# I94100_v1_3 register map
File version: 1.0
Registers are 32-bit, read-write, reset 0x0 unless marked. A register's access mark holds for its fields unless they carry their own. Offsets are from the block's base; [hi:lo] are bit positions; {n}, {i} and the like mark numbered series; 'fields as' and 'values as' point back to an identical list; <NAME> marks a mode.

## TMR23 — TIMER Register Map
Base 0x40051000
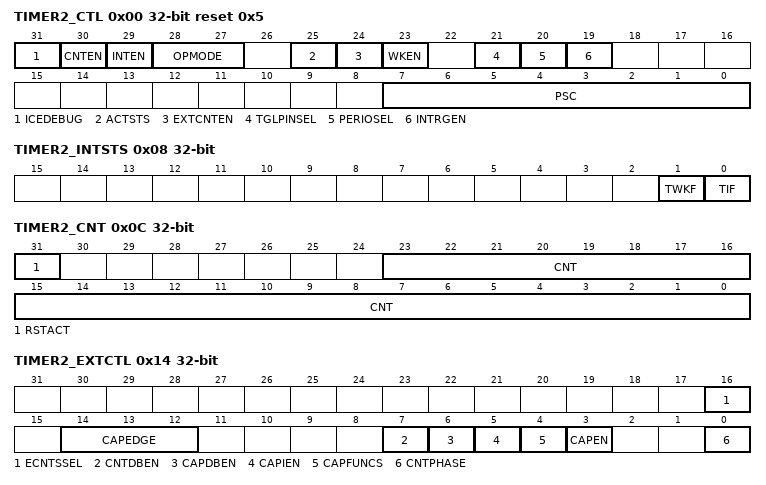
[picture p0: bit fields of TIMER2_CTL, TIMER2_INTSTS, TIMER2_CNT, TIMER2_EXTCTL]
0x00 TIMER2_CTL reset 0x5 — Timer2 Control Register
  [31] ICEDEBUG — ICE Debug Mode Acknowledge Disable Control (Write Protected). TIMER counter will keep going no matter CPU is held by ICE or not. Note: This bit is write protected. Refer to the SYS_REGLCTL register.
    0=ICE debug mode acknowledgement effects TIMER counting; 1=ICE debug mode acknowledgement Disabled
  [30] CNTEN — Timer Counting Enable Bit. Note3: Set enable/disable this bit needs 2 * TMR_CLK period to become active, user can read ACTSTS (TIMERx_CTL[25]) to check enable/disable command is completed or not.
    0=Stops/Suspends counting; 1=Starts counting
  [29] INTEN — Timer Interrupt Enable Bit. Note: If this bit is enabled, when the timer time-out interrupt flag TIF is set to 1, the timer interrupt signal is generated and inform to CPU.
    0=Timer time-out interrupt Disabled; 1=Timer time-out interrupt Enabled
  [28:27] OPMODE — Timer Counting Mode Select
    0=The Timer controller is operated in One-shot mode; 1=The Timer controller is operated in Periodic mode; 2=The Timer controller is operated in Toggle-output mode; 3=The Timer controller is operated in Continuous Counting mode
  [25] ACTSTS ro — Timer Active Status Bit (Read Only). This bit indicates the 24-bit up counter status. Note: This bit may active when CNT 0 transition to CNT 1.
    0=24-bit up counter is not active; 1=24-bit up counter is active
  [24] EXTCNTEN — Event Counter Mode Enable Bit. This bit is for external counting pin function enabled. Note: When timer is used as an event counter, this bit should be set to 1 and select PCLK as timer clock source.
    0=Event counter mode Disabled; 1=Event counter mode Enabled
  [23] WKEN — Wake-up Function Enable Bit. If this bit is set to 1, while timer interrupt flag TIF (TIMERx_INTSTS[0]) is 1 and INTEN (TIMERx_CTL[29]) is enabled, the timer interrupt signal will generate a wake-up trigger event to CPU.
    0=Wake-up function Disabled if timer interrupt signal generated; 1=Wake-up function Enabled if timer interrupt signal generated
  [21] TGLPINSEL — Toggle-output Pin Select
    0=Toggle mode output to TMx (Timer Event Counter Pin); 1=Toggle mode output to TMx_EXT (Timer External Capture Pin)
  [20] PERIOSEL — Periodic Mode Behavior Selection Enable Bit. If updated CMPDAT value < CNT, CNT will be reset to default value.
    0=The behavior selection in periodic mode is Disabled; 1=The behavior selection in periodic mode is Enabled
  [19] INTRGEN — Inter-timer Trigger Mode Enable Control. Setting this bit will enable the inter-timer trigger capture function. The Timer0/2 will be in event counter mode and counting with external clock source or event.Also, Timer1/3 will be in trigger-counting mode of capture function. Note: For Timer1/3, this bit is ignored and the read back value is always 0.
    0=Inter-Timer Trigger Capture mode Disabled; 1=Inter-Timer Trigger Capture mode Enabled
  [7:0] PSC — Prescale Counter. Note: Overwriting prescale counter value will reset internal 8-bit prescale counter and 24-bit up counter value.
0x04 TIMER2_CMP — Timer2 Comparator Register
  [23:0] CMPDAT — Timer Comparator Value. CMPDAT is a 24-bit compared value register. When the internal 24-bit up counter value is equal to CMPDAT value, the TIF (TIMERx_INTSTS[0] Timer Interrupt Flag) will set to 1. Note1: Never write 0x0 or 0x1 in CMPDAT field, or the core will run into unknown state. Note2: When timer is operating at continuous counting mode, the 24-bit up counter will keep counting continuously even if user writes a new value into CMPDAT field. But if timer is operating at other modes, the 24-bit up counter will restart counting from 0 and using newest CMPDAT value to be the timer compared value while user writes a new value into CMPDAT field.
0x08 TIMER2_INTSTS — Timer2 Interrupt Status Register
  [1] TWKF — Timer Wake-up Flag. This bit indicates the interrupt wake-up flag status of timer. Note: This bit is cleared by writing 1 to it.
    0=Timer does not cause CPU wake-up; 1=CPU wake-up from Power-down mode if timer time-out interrupt signal generated
  [0] TIF — Timer Interrupt Flag. This bit indicates the interrupt flag status of Timer while 24-bit timer up counter CNT (TIMERx_CNT[23:0]) value reaches to CMPDAT (TIMERx_CMP[23:0]) value. Note: This bit is cleared by writing 1 to it.
    0=No effect; 1=CNT value matches the CMPDAT value
0x0C TIMER2_CNT — Timer2 Data Register
  [31] RSTACT ro — Timer Data Register Reset Active (Read Only). This bit indicates if the counter reset operation active. When user writes this CNT register, timer starts to reset its internal 24-bit timer up-counter to 0 and reload 8-bit pre-scale counter. At the same time, timer set this flag to 1 to indicate the counter reset operation is in progress. Once the counter reset operation done, timer clear this bit to 0 automatically. Note: This bit is read only.
    0=Reset operation is done; 1=Reset operation triggered by writing TIMERx_CNT is in progress
  [23:0] CNT — Timer Data Register. Read operation. Read this register to get CNT value. For example: If EXTCNTEN (TIMERx_CTL[24] ) is 0, user can read CNT value for getting current 24-bit counter value. If EXTCNTEN (TIMERx_CTL[24] ) is 1, user can read CNT value for getting current 24-bit event input counter value. Write operation. Writing any value to this register will reset current CNT value to 0 and reload internal 8-bit prescale counter.
0x10 TIMER2_CAP ro — Timer2 Capture Data Register
  [23:0] CAPDAT — Timer Capture Data Register (Read Only). When CAPEN (TIMERx_EXTCTL[3]) bit is set, CAPFUNCS (TIMERx_EXTCTL[4]) bit is 0, and a transition on TMx_EXT pin matched the CAPEDGE (TIMERx_EXTCTL[14:12]) setting, CAPIF (TIMERx_EINTSTS[0]) will set to 1 and the current timer counter value CNT (TIMERx_CNT[23:0]) will be auto-loaded into this CAPDAT field.
0x14 TIMER2_EXTCTL — Timer2 External Control Register
  [16] ECNTSSEL — Event Counter Source Selection to Trigger Event Counter Function
    0=Event Counter input source is from TMx (x= 0~3) pin; 1=Reserved Event Counter input source is from USB internal SOF output signal
  [14:12] CAPEDGE — Timer External Capture Pin Edge Detect. When first capture event is generated, the CNT (TIMERx_CNT[23:0]) will be reset to 0 and first CAPDAT (TIMERx_CAP[23:0]) should be to 0.
    0=Capture event occurred when detect falling edge transfer on TMx_EXT (x= 0~3) pin; 1=Capture event occurred when detect rising edge transfer on TMx_EXT (x= 0~3) pin; 2=Capture event occurred when detect both falling and rising edge transfer on TMx_EXT (x= 0~3) pin, and first capture event occurred at falling edge transfer; 3=Capture event occurred when detect both rising and falling edge transfer on TMx_EXT (x= 0~3) pin, and first capture event occurred at rising edge transfer; 6=First capture event occurred at falling edge, follows capture events are at rising edge transfer on TMx_EXT (x= 0~3) pin; 7=First capture event occurred at rising edge, follows capture events are at falling edge transfer on TMx_EXT (x= 0~3) pin
  [7] CNTDBEN — Timer Counter Pin De-bounce Enable Bit. Note: If this bit is enabled, the edge detection of TMx pin is detected with de-bounce circuit.
    0=TMx (x= 0~3) pin de-bounce Disabled; 1=TMx (x= 0~3) pin de-bounce Enabled
  [6] CAPDBEN — Timer External Capture Pin De-bounce Enable Bit. Note: If this bit is enabled, the edge detection of TMx_EXT pin output is detected with de-bounce circuit.
    0=TMx_EXT (x= 0~3) pin de-bounce Disabled; 1=TMx_EXT (x= 0~3) pin de-bounce Enabled
  [5] CAPIEN — Timer External Capture Interrupt Enable Bit
    0=TMx_EXT (x= 0~3) pin detection Interrupt Disabled; 1=TMx_EXT (x= 0~3) pin detection Interrupt Enabled
  [4] CAPFUNCS — Capture Function Selection
    0=External Capture Mode Enabled; 1=External Reset Mode Enabled
  [3] CAPEN — Timer External Capture Pin Enable Bit. This bit enables the TMx_EXT capture pin input function.
    0=TMx_EXT (x= 0~3) pin Disabled; 1=TMx_EXT (x= 0~3) pin Enabled
  [0] CNTPHASE — Timer External Count Phase
    0=A falling edge of external counting pin will be counted; 1=A rising edge of external counting pin will be counted
0x18 TIMER2_EINTSTS — Timer2 External Interrupt Status Register
  [0] CAPIF — Timer External Capture Interrupt Flag. This bit indicates the timer external capture interrupt flag status. Note3: There is a new incoming capture event detected before CPU clearing the CAPIF status. If the above condition occurred, the Timer will keep register TIMERx_CAP unchanged and drop the new capture value.
    0=TMx_EXT (x= 0~3) pin interrupt did not occur; 1=TMx_EXT (x= 0~3) pin interrupt occurred
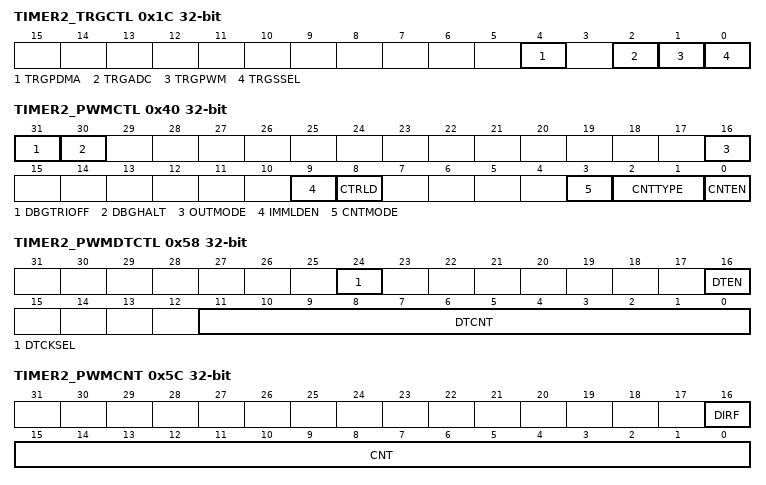
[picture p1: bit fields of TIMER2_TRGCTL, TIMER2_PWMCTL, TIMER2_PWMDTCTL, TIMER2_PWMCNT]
0x1C TIMER2_TRGCTL — Timer2 Trigger Control Register
  [4] TRGPDMA — Trigger PDMA Enable Bit. If this bit is set to 1, each timer time-out event or capture event can be triggered PDMA transfer.
    0=Timer interrupt trigger PDMA Disabled; 1=Timer interrupt trigger PDMA Enabled
  [2] TRGADC — Trigger ADC Enable Bit. If this bit is set to 1, each timer time-out event or capture event can be triggered ADC conversion.
    0=Timer interrupt trigger ADC Disabled; 1=Timer interrupt trigger ADC Enabled
  [1] TRGPWM — Trigger PWM Enable Bit. If this bit is set to 1, each timer time-out event or capture event can be as PWM counter clock source.
    0=Timer interrupt trigger PWM Disabled; 1=Timer interrupt trigger PWM Enabled
  [0] TRGSSEL — Trigger Source Select Bit. This bit is used to select internal trigger source is form timer time-out interrupt signal or capture interrupt signal.
    0=Time-out interrupt signal is used to internal trigger PWM, PDMA, and ADC; 1=Capture interrupt signal is used to internal trigger PWM, PDMA, and ADC
0x20 TIMER2_ALTCTL — Timer2 Alternative Control Register
  [0] FUNCSEL — Function Selection. Note: When timer is used as PWM, the clock source of time controller will be forced to PCLKx automatically.
    0=Timer controller is used as timer function; 1=Timer controller is used as PWM function
0x40 TIMER2_PWMCTL — Timer2 PWM Control Register
  [31] DBGTRIOFF — ICE Debug Mode Acknowledge Disable Bit (Write Protected). PWM output pin will keep output no matter ICE debug mode acknowledged or not. Note: This register is write protected. Refer to SYS_REGLCTL register.
    0=ICE debug mode acknowledgement effects PWM output; 1=ICE debug mode acknowledgement disabled
  [30] DBGHALT — ICE Debug Mode Counter Halt (Write Protected). If debug mode counter halt is enabled, PWM counter will keep current value until exit ICE debug mode. Note: This register is write protected. Refer to SYS_REGLCTL register.
    0=ICE debug mode counter halt disable; 1=ICE debug mode counter halt enable
  [16] OUTMODE — PWM Output Mode. This bit controls the output mode of corresponding PWM channel.
    0=PWM independent mode; 1=PWM complementary mode
  [9] IMMLDEN — Immediately Load Enable Bit. Note: If IMMLDEN is enabled, CTRLD will be invalid.
    0=PERIOD will load to PBUF when current PWM period is completed no matter CTRLD is enabled/disabled. If CTRLD is disabled, CMP will load to CMPBUF when current PWM period is completed; if CTRLD is enabled in up-down count type, CMP will load to CMPBUF at the center point of current period; 1=PERIOD/CMP will load to PBUF/CMPBUF immediately when user update PERIOD/CMP
  [8] CTRLD — Center Re-load. In up-down count type, PERIOD will load to PBUF when current PWM period is completed always and CMP will load to CMPBUF at the center point of current period.
  [3] CNTMODE — PWM Counter Mode
    0=Auto-reload mode; 1=One-shot mode
  [2:1] CNTTYPE — PWM Counter Behavior Type
    0=Up count type; 1=Down count type; 2=Up-down count type; 3=Reserved. Do not use
  [0] CNTEN — PWM Counter Enable Bit
    0=PWM counter and clock prescale Stop Running; 1=PWM counter and clock prescale Start Running
0x44 TIMER2_PWMCLKSRC — Timer2 PWM Counter Clock Source Register
  [2:0] CLKSRC — PWM Counter Clock Source Select. The PWM counter clock source can be selected from TMRx_CLK or internal timer time-out or capture event. Note: If TIMER0 PWM function is enabled, the PWM counter clock source can be selected from TMR0_CLK, TIMER1 interrupt events, TIMER2 interrupt events, or TIMER3 interrupt events.
    0=TMRx_CLK; {v}=Internal TIMER{v-1} time-out or capture event (v=1..4)
0x48 TIMER2_PWMCLKPSC — Timer2 PWM Counter Clock Pre-scale Register
  [11:0] CLKPSC — PWM Counter Clock Pre-scale. The active clock of PWM counter is decided by counter clock prescale and divided by (CLKPSC + 1). If CLKPSC is 0, then there is no scaling in PWM counter clock source.
0x4C TIMER2_PWMCNTCLR — Timer2 PWM Clear Counter Register
  [0] CNTCLR — Clear PWM Counter Control Bit. It is automatically cleared by hardware.
    0=No effect; 1=Clear 16-bit PWM counter to 0x10000 in up and up-down count type and reset counter value to PERIOD in down count type
0x50 TIMER2_PWMPERIOD
  [15:0] PERIOD — PWM Period Register. In up count type: PWM counter counts from 0 to PERIOD, and restarts from 0. In down count type: PWM counter counts from PERIOD to 0, and restarts from PERIOD. In up-down count type: PWM counter counts from 0 to PERIOD, then decrements to 0 and repeats again. In up and down count type: Note: User should take care DIRF (TIMERx_PWMCNT[16]) bit in up/down/up-down count type to monitor current counter direction in each count type.
0x54 TIMER2_PWMCMPDAT — Timer2 PWM Comparator Register
  [15:0] CMP — PWM Comparator Register. PWM CMP is used to compare with PWM CNT to generate PWM output waveform, interrupt events and trigger ADC to start convert.
0x58 TIMER2_PWMDTCTL — Timer2 PWM Dead-time Control Register
  [24] DTCKSEL — Dead-time Clock Select (Write Protected). Note: This register is write protected. Refer to SYS_REGLCTL register.
    0=Dead-time clock source from TMRx_PWMCLK without counter clock prescale; 1=Dead-time clock source from TMRx_PWMCLK with counter clock prescale
  [16] DTEN — Enable Dead-time Insertion for PWMx_CH0 and PWMx_CH1 (Write Protected). Dead-time insertion function is only active when PWM complementary mode is enabled. If dead- time insertion is inactive, the outputs of PWMx_CH0 and PWMx_CH1 are complementary without any delay. Note: This register is write protected. Refer to SYS_REGLCTL register.
    0=Dead-time insertion Disabled on the pin pair; 1=Dead-time insertion Enabled on the pin pair
  [11:0] DTCNT — Dead-time Counter (Write Protected). The dead-time can be calculated from the following two formulas: Note: This register is write protected. Refer to SYS_REGLCTL register.
0x5C TIMER2_PWMCNT ro — Timer2 PWM Counter Register
  [16] DIRF — PWM Counter Direction Indicator Flag (Read Only)
    0=Counter is active in down count; 1=Counter is active up count
  [15:0] CNT — PWM Counter Value Register (Read Only). User can monitor CNT to know the current counter value in 16-bit period counter.
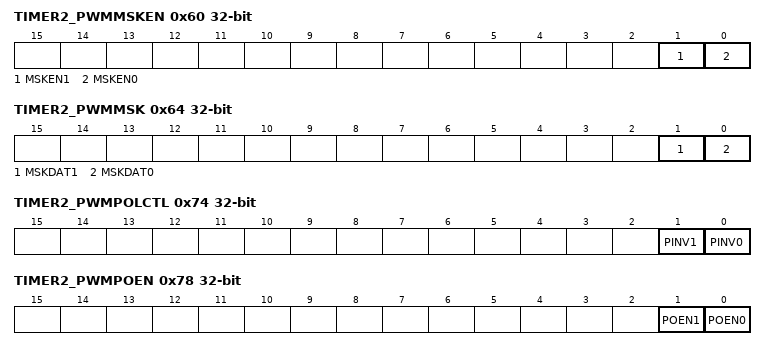
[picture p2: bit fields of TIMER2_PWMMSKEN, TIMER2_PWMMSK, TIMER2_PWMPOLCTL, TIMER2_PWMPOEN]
0x60 TIMER2_PWMMSKEN — Timer2 PWM Output Mask Enable Register
  [1] MSKEN1 — PWMx_CH1 Output Mask Enable Bit. The PWMx_CH1 output signal will be masked when this bit is enabled. The PWMx_CH1 will output MSKDAT1 (TIMER_PWMMSK[1]) data.
    0=PWMx_CH1 output signal is non-masked; 1=PWMx_CH1 output signal is masked and output MSKDAT1 data
  [0] MSKEN0 — PWMx_CH0 Output Mask Enable Bit. The PWMx_CH0 output signal will be masked when this bit is enabled. The PWMx_CH0 will output MSKDAT0 (TIMER_PWMMSK[0]) data.
    0=PWMx_CH0 output signal is non-masked; 1=PWMx_CH0 output signal is masked and output MSKDAT0 data
0x64 TIMER2_PWMMSK — Timer2 PWM Output Mask Data Control Register
  [1] MSKDAT1 — PWMx_CH1 Output Mask Data Control Bit
    0=Output logic Low to PWMx_CH1; 1=Output logic High to PWMx_CH1
  [0] MSKDAT0 — PWMx_CH0 Output Mask Data Control Bit
    0=Output logic Low to PWMx_CH0; 1=Output logic High to PWMx_CH0
0x74 TIMER2_PWMPOLCTL — Timer2 PWM Pin Output Polar Control Register
  [1] PINV1 — PWMx_CH1 Output Pin Polar Control Bit. The bit is used to control polarity state of PWMx_CH1 output pin.
    0=PWMx_CH1 output pin polar inverse Disabled; 1=PWMx_CH1 output pin polar inverse Enabled
  [0] PINV0 — PWMx_CH0 Output Pin Polar Control Bit. The bit is used to control polarity state of PWMx_CH0 output pin.
    0=PWMx_CH0 output pin polar inverse Disabled; 1=PWMx_CH0 output pin polar inverse Enabled
0x78 TIMER2_PWMPOEN — Timer2 PWM Pin Output Enable Register
  [1] POEN1 — PWMx_CH1 Output Pin Enable Bit
    0=PWMx_CH1 pin at tri-state mode; 1=PWMx_CH1 pin in output mode
  [0] POEN0 — PWMx_CH0 Output Pin Enable Bit
    0=PWMx_CH0 pin at tri-state mode; 1=PWMx_CH0 pin in output mode
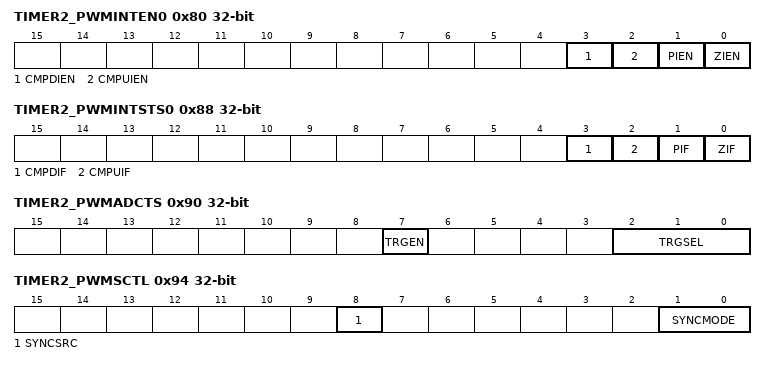
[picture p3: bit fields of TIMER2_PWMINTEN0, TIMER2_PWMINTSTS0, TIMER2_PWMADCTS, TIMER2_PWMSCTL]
0x80 TIMER2_PWMINTEN0 — Timer2 PWM Interrupt Enable Register 0
  [3] CMPDIEN — PWM Compare Down Count Interrupt Enable Bit
    0=Compare down count interrupt Disabled; 1=Compare down count interrupt Enabled
  [2] CMPUIEN — PWM Compare Up Count Interrupt Enable Bit
    0=Compare up count interrupt Disabled; 1=Compare up count interrupt Enabled
  [1] PIEN — PWM Period Point Interrupt Enable Bit. Note: When in up-down count type, period point means the center point of current PWM period.
    0=Period point interrupt Disabled; 1=Period point interrupt Enabled
  [0] ZIEN — PWM Zero Point Interrupt Enable Bit
    0=Zero point interrupt Disabled; 1=Zero point interrupt Enabled
0x88 TIMER2_PWMINTSTS0 — Timer2 PWM Interrupt Status Register 0
  [3] CMPDIF — PWM Compare Down Count Interrupt Flag. This bit is set by hardware when TIMERx_PWM counter in down count direction and reaches CMP. Note1: If CMP equal to PERIOD, there is no CMPDIF flag in down count type. Note2: This bit is cleared by writing 1 to it.
  [2] CMPUIF — PWM Compare Up Count Interrupt Flag. This bit is set by hardware when TIMERx_PWM counter in up count direction and reaches CMP. Note1: If CMP equal to PERIOD, there is no CMPUIF flag in up count type and up-down count type.. Note2: This bit is cleared by writing 1 to it.
  [1] PIF — PWM Period Point Interrupt Flag. This bit is set by hardware when TIMERx_PWM counter reaches PERIOD. Note1: When in up-down count type, PIF flag means the center point flag of current PWM period. Note2: This bit is cleared by writing 1 to it.
  [0] ZIF — PWM Zero Point Interrupt Flag. This bit is set by hardware when TIMERx_PWM counter reaches zero. Note: This bit is cleared by writing 1 to it.
0x90 TIMER2_PWMADCTS — Timer2 PWM ADC Trigger Source Select Register
  [7] TRGEN — PWM Counter Event Trigger ADC Conversion Enable Bit
    0=PWM counter event trigger ADC conversion Disabled; 1=PWM counter event trigger ADC conversion Enabled
  [2:0] TRGSEL — PWM Counter Event Source Select to Trigger ADC Conversion
    0=Trigger ADC conversion at zero point (ZIF); 1=Trigger ADC conversion at period point (PIF); 2=Trigger ADC conversion at zero or period point (ZIF or PIF); 3=Trigger ADC conversion at compare up count point (CMPUIF); 4=Trigger ADC conversion at compare down count point (CMPDIF)
0x94 TIMER2_PWMSCTL — Timer2 PWM Synchronous Control Register
  [8] SYNCSRC — PWM Synchronous Counter Start/Clear Source Select. Note1: If TIMER0/1/2/3 PWM counter synchronous source are from TIMER0, TIMER0_PWMSCTL[8], TIMER1_PWMSCTL[8], TIMER2_PWMSCTL[8] and TIMER3_PWMSCTL[8] should be 0. Note2: If TIMER0/1/ PWM counter synchronous source are from TIMER0, TIMER0_PWMSCTL[8] and TIMER1_PWMSCTL[8] should be set 0, and TIMER2/3/ PWM counter synchronous source are from TIMER2, TIMER2_PWMSCTL[8] and TIMER3_PWMSCTL[8] should be set 1.
    0=Counter synchronous start/clear by trigger STRGEN (TIMER0_PWMSTRG[0]); 1=Counter synchronous start/clear by trigger STRGEN (TIMER2_PWMSTRG[0])
  [1:0] SYNCMODE — PWM Synchronous Mode Enable Select
    0=PWM synchronous function Disabled; 1=PWM synchronous counter start function Enabled; 2=Reserved. Do not use; 3=PWM synchronous counter clear function Enabled
0x98 TIMER2_PWMSTRG wo — Timer2 PWM Synchronous Trigger Register
  [0] STRGEN — PWM Counter Synchronous Trigger Enable Bit (Write Only). PMW counter synchronous function is used to make selected PWM channels (include TIMER0/1/2/3 PWM, TIMER0/1 PWM and TIMER2/3 PWM) start counting or clear counter at the same time according to TIMERx_PWMSCTL setting. Note: This bit is only available in TIMER0 and TIMER2.
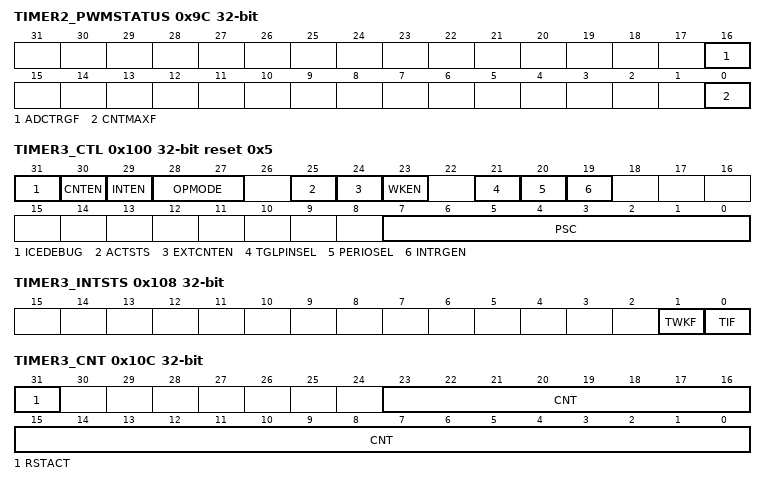
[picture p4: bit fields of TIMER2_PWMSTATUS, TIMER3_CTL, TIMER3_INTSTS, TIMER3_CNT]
0x9C TIMER2_PWMSTATUS
  [16] ADCTRGF — Trigger ADC Start Conversion Flag. Note: This bit is cleared by writing 1 to it.
    0=PWM counter event trigger ADC start conversion is not occurred; 1=PWM counter event trigger ADC start conversion has occurred
  [0] CNTMAXF — PWM Counter Equal to 0xFFFF Flag. Note: This bit is cleared by writing 1 to it.
    0=Indicates the PWM counter value never reached its maximum value 0xFFFF; 1=Indicates the PWM counter value has reached its maximum value
0xA0 TIMER2_PWMPBUF ro — Timer2 PWM Period Buffer Register
  [15:0] PBUF — PWM Period Buffer Register (Read Only). Used as PERIOD active register.
0xA4 TIMER2_PWMCMPBUF ro — Timer2 PWM Comparator Buffer Register
  [15:0] CMPBUF — PWM Comparator Buffer Register (Read Only). Used as CMP active register.
0x100 TIMER3_CTL reset 0x5 — Timer3 Control Register
  fields as TIMER2_CTL
0x104 TIMER3_CMP — Timer3 Comparator Register
  fields as TIMER2_CMP
0x108 TIMER3_INTSTS — Timer3 Interrupt Status Register
  fields as TIMER2_INTSTS
0x10C TIMER3_CNT — Timer3 Data Register
  fields as TIMER2_CNT
0x110 TIMER3_CAP ro — Timer3 Capture Data Register
  fields as TIMER2_CAP
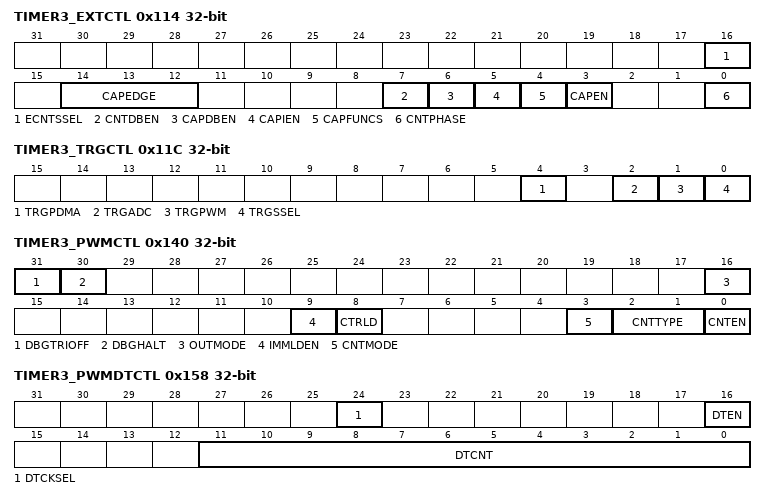
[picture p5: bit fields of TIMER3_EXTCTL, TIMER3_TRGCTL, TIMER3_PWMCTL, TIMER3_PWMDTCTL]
0x114 TIMER3_EXTCTL — Timer3 External Control Register
  fields as TIMER2_EXTCTL
0x118 TIMER3_EINTSTS — Timer3 External Interrupt Status Register
  fields as TIMER2_EINTSTS
0x11C TIMER3_TRGCTL — Timer3 Trigger Control Register
  fields as TIMER2_TRGCTL
0x120 TIMER3_ALTCTL — Timer3 Alternative Control Register
  fields as TIMER2_ALTCTL
0x140 TIMER3_PWMCTL — Timer3 PWM Control Register
  fields as TIMER2_PWMCTL
0x144 TIMER3_PWMCLKSRC — Timer3 PWM Counter Clock Source Register
  fields as TIMER2_PWMCLKSRC
0x148 TIMER3_PWMCLKPSC — Timer3 PWM Counter Clock Pre-scale Register
  fields as TIMER2_PWMCLKPSC
0x14C TIMER3_PWMCNTCLR — Timer3 PWM Clear Counter Register
  fields as TIMER2_PWMCNTCLR
0x150 TIMER3_PWMPERIOD
  fields as TIMER2_PWMPERIOD
0x154 TIMER3_PWMCMPDAT — Timer3 PWM Comparator Register
  fields as TIMER2_PWMCMPDAT
0x158 TIMER3_PWMDTCTL — Timer3 PWM Dead-time Control Register
  fields as TIMER2_PWMDTCTL
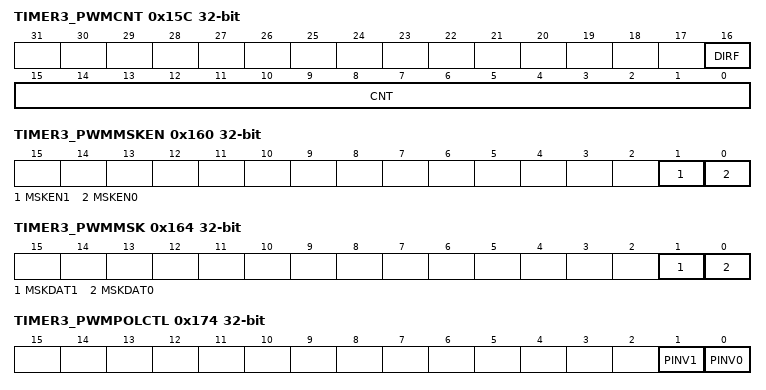
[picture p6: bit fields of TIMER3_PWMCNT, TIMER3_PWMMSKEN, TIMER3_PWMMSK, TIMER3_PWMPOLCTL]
0x15C TIMER3_PWMCNT ro — Timer3 PWM Counter Register
  fields as TIMER2_PWMCNT
0x160 TIMER3_PWMMSKEN — Timer3 PWM Output Mask Enable Register
  fields as TIMER2_PWMMSKEN
0x164 TIMER3_PWMMSK — Timer3 PWM Output Mask Data Control Register
  fields as TIMER2_PWMMSK
0x174 TIMER3_PWMPOLCTL — Timer3 PWM Pin Output Polar Control Register
  fields as TIMER2_PWMPOLCTL
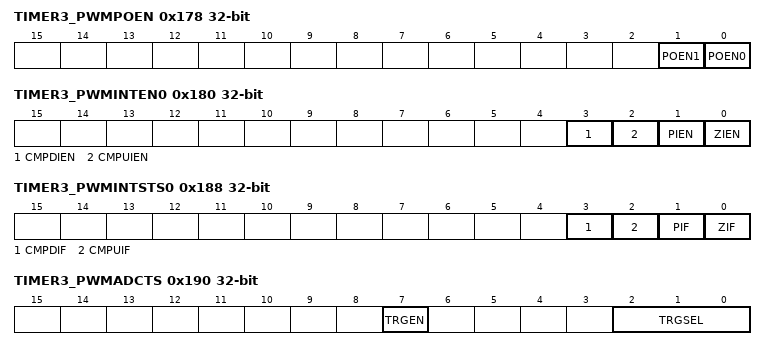
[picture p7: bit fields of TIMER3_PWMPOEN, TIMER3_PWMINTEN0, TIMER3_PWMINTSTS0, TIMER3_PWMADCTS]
0x178 TIMER3_PWMPOEN — Timer3 PWM Pin Output Enable Register
  fields as TIMER2_PWMPOEN
0x180 TIMER3_PWMINTEN0 — Timer3 PWM Interrupt Enable Register 0
  fields as TIMER2_PWMINTEN0
0x188 TIMER3_PWMINTSTS0 — Timer3 PWM Interrupt Status Register 0
  fields as TIMER2_PWMINTSTS0
0x190 TIMER3_PWMADCTS — Timer3 PWM ADC Trigger Source Select Register
  fields as TIMER2_PWMADCTS
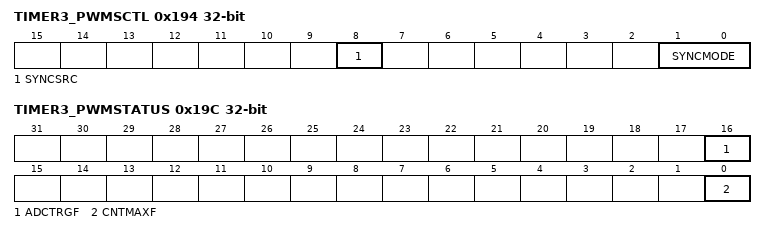
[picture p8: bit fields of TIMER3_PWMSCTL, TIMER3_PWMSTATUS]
0x194 TIMER3_PWMSCTL — Timer3 PWM Synchronous Control Register
  fields as TIMER2_PWMSCTL
0x198 TIMER3_PWMSSTRG wo — Timer3 PWM Synchronous Start Trigger Register
0x19C TIMER3_PWMSTATUS
  fields as TIMER2_PWMSTATUS
0x1A0 TIMER3_PWMPBUF ro — Timer3 PWM Period Buffer Register
  fields as TIMER2_PWMPBUF
0x1A4 TIMER3_PWMCMPBUF ro — Timer3 PWM Comparator Buffer Register
  fields as TIMER2_PWMCMPBUF
